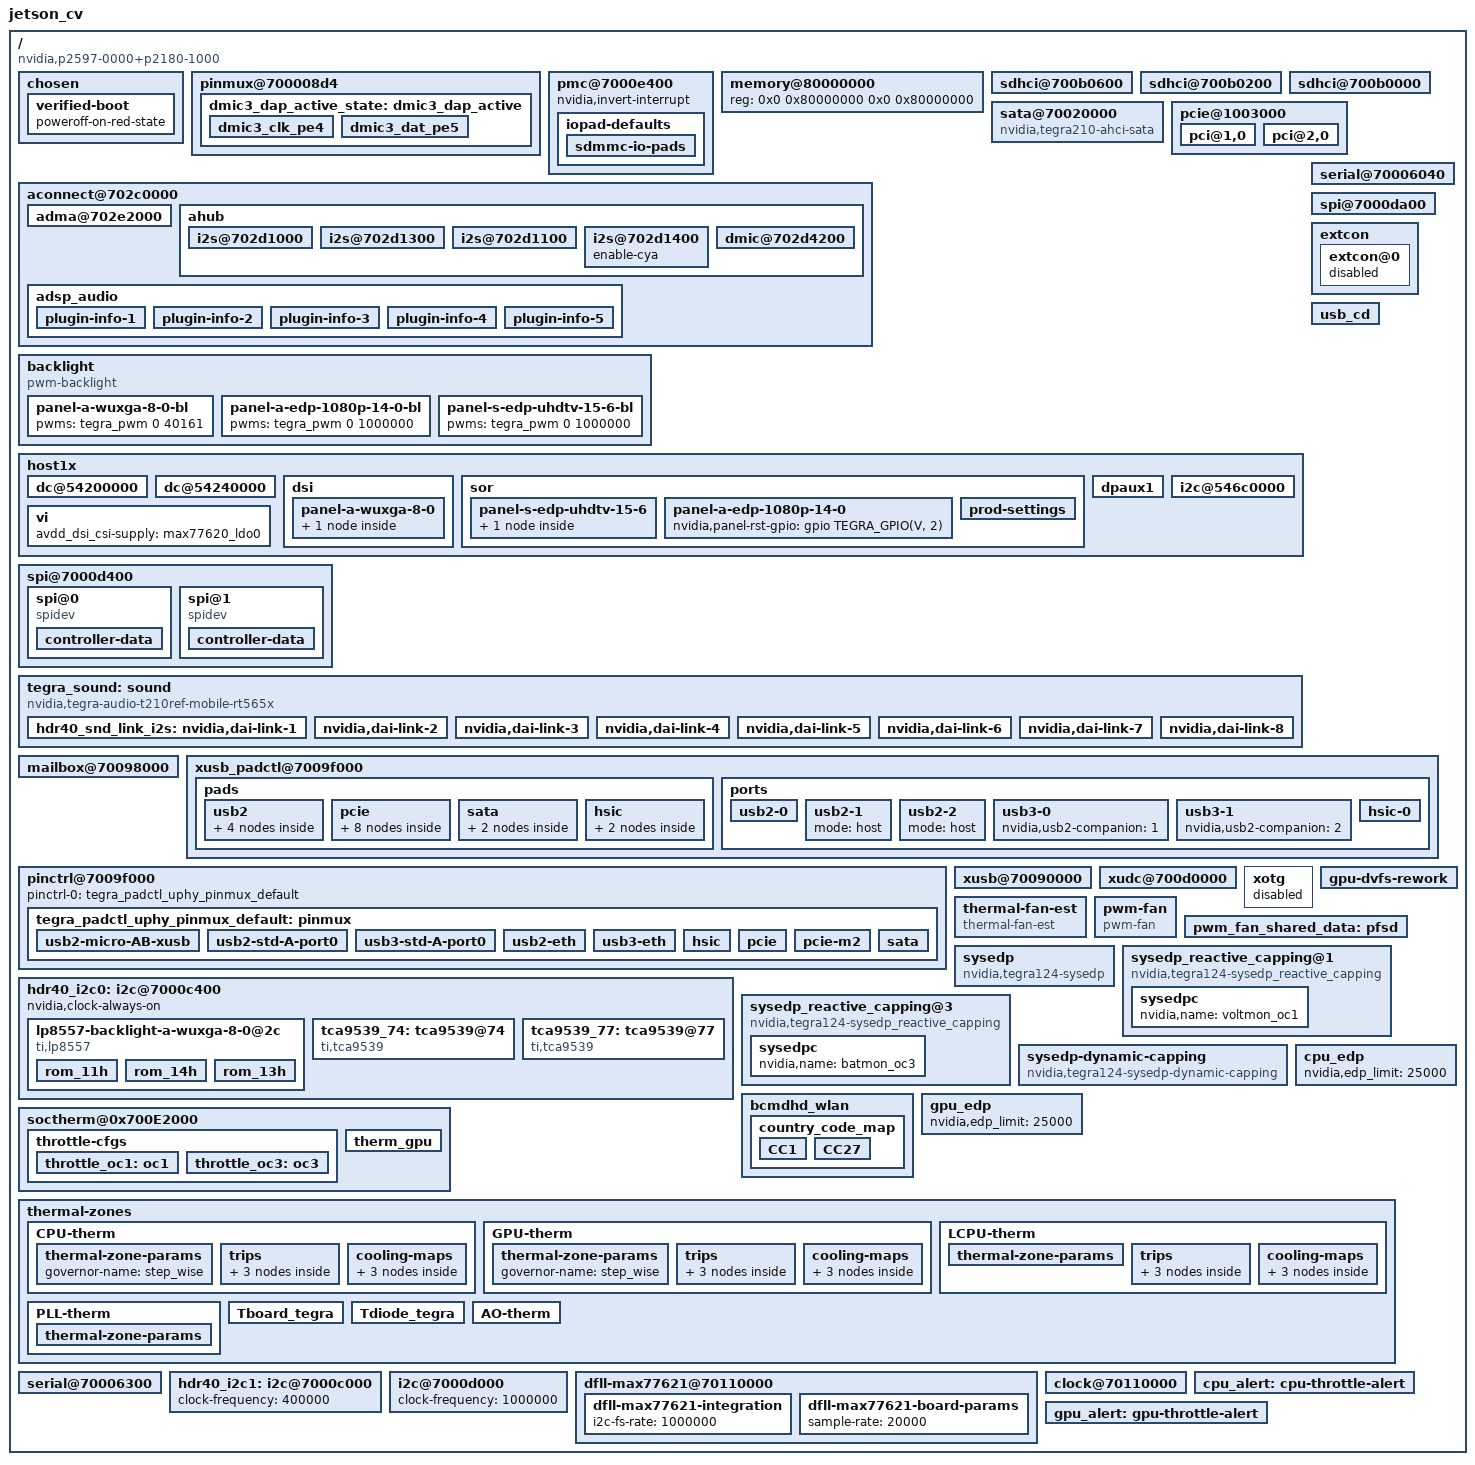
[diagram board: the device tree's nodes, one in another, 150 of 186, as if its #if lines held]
/*
 * arch/arm64/boot/dts/tegra210-jetson-cv-base-p2597-2180-a00.dts
 *
 * Copyright (c) 2015-2020, NVIDIA CORPORATION.  All rights reserved.
 *
 * This program is free software; you can redistribute it and/or modify
 * it under the terms of the GNU General Public License as published by
 * the Free Software Foundation; version 2 of the License.
 *
 * This program is distributed in the hope that it will be useful, but WITHOUT
 * ANY WARRANTY; without even the implied warranty of MERCHANTABILITY or
 * FITNESS FOR A PARTICULAR PURPOSE.  See the GNU General Public License for
 * more details.
 *
 */

/dts-v1/;

/memreserve/ 0x80000000 0x00020000;

#include "tegra210-jetson-common.dtsi"
#include <tegra210-soc/tegra210-audio.dtsi>
#include "jetson-platforms/tegra210-jetson-cv-power-tree-p2597-2180-a00.dtsi"
#include "jetson-platforms/tegra210-jetson-cv-pinmux-p2597-2180-a00.dtsi"
#include "jetson-platforms/tegra210-jetson-cv-gpio-p2597-2180-a00.dtsi"
#include "jetson-platforms/tegra210-jetson-cv-prods.dtsi"
#include "jetson-platforms/tegra210-comms-p2530-0930.dtsi"
#include "jetson-platforms/tegra210-jetson-cv-camera-modules.dtsi"
#include "jetson-platforms/tegra210-pwm-fan-p2530-0930.dtsi"
#include <panels/panel-a-wuxga-8-0.dtsi>
#include <panels/panel-a-edp-1080p-14-0.dtsi>
#include <panels/panel-s-edp-uhdtv-15-6.dtsi>
#include <t210-common-platforms/tegra210-ers-hdmi-e2190-1100-a00.dtsi>
#include <tegra210-soc/tegra210-sdhci.dtsi>
#include "jetson-platforms/tegra210-p2180-common.dtsi"
#include "jetson-platforms/tegra210-thermal-fan-est-p2530-0930.dtsi"
#include "jetson-platforms/tegra210-jetson-cv-keys-p2597-2180-a00.dtsi"
#include <dt-bindings/iio/meter/ina3221x.h>
#include <t210-common-platforms/tegra210-otg-gpio-detection-extcon.dtsi>
#include "jetson-platforms/tegra210-jetson-cv-emc-p2180-1000-a00.dtsi"
#include <tegra210-soc/tegra210-edp.dtsi>
#include <t210-common-platforms/tegra210-sysedp.dtsi>
#include <t210-common-platforms/tegra210-thermal-nct72-p2530.dtsi>
#include <t210-common-platforms/tegra210-thermal-userspace-alert.dtsi>
#include <tegra210-soc/tegra210-thermal-Tboard-Tdiode.dtsi>
#include "jetson-platforms/tegra210-jetson-cv-powermon-p2180-1000-a00.dtsi"
#include "jetson-platforms/tegra210-jetson-cv-powermon-p2597.dtsi"
#include <t210-common-platforms/tegra210-cpufreq.dtsi>
#include "jetson-platforms/tegra210-jetson-cv-super-module-e2614.dtsi"
#include "jetson-plugin-manager/tegra210-jetson-cv-eeprom-manager.dtsi"
#include "jetson-plugin-manager/tegra210-jetson-cv-camera-plugin-manager.dtsi"
#include "jetson-plugin-manager/tegra210-jetson-cv-plugin-manager.dtsi"

/ {
	model = "jetson_cv";
	compatible = "nvidia,p2597-0000+p2180-1000", "nvidia,jetson-cv", "nvidia,tegra210";
	nvidia,dtsfilename = __FILE__;

	#address-cells = <2>;
	#size-cells = <2>;

	chosen {
		board-has-eeprom;
		firmware-blob-partition = "RP4";
		stdout-path = &uarta;
		verified-boot {
			poweroff-on-red-state;
		};
	};

	pinmux@700008d4 {
		/* Dynamic pinmux config for DMIC3 */
		dmic3_dap_active_state: dmic3_dap_active {
			dmic3_clk_pe4 {
				nvidia,pins = "dmic3_clk_pe4";
				nvidia,function = "dmic3";
			};

			dmic3_dat_pe5 {
				nvidia,pins = "dmic3_dat_pe5";
				nvidia,function = "dmic3";
			};
		};
	};

	pmc@7000e400 {
		nvidia,invert-interrupt;

		iopad-defaults {
			sdmmc-io-pads {
				pins = "sdmmc1", "sdmmc3";
				nvidia,enable-voltage-switching;
			};
		};
	};

	memory@80000000 {
		device_type = "memory";
		reg = < 0x0 0x80000000 0x0 0x80000000 >;
	};

	sdhci@700b0600 { /* SDMMC4 for EMMC */
		uhs-mask = <0x0>;
		built-in;
		power-off-rail;
		status = "okay";
		bus-width = <8>;
		non-removable;
	};

	sdhci@700b0200 { /* SDMMC2 for Wifi */
		uhs-mask = <0x8>;
		power-off-rail;
		status = "okay";
	};

	sdhci@700b0000 { /* SDMMC1 for SD card */
		uhs-mask = <0xc>;
		power-off-rail;
		nvidia,update-pinctrl-settings;
		nvidia,sd-device;
		wp-gpios = <&gpio TEGRA_GPIO(Z, 4) 0>;
		status = "okay";
	};

#if TEGRA_AUDIO_BUS_DT_VERSION >= DT_VERSION_2
	aconnect@702c0000 {
#endif
	adma@702e2000  {
		status = "okay";
	};

	ahub {
		i2s@702d1000 {
			pinctrl-names = "dap_active", "dap_inactive";
			pinctrl-0 = <>;
			pinctrl-1 = <>;
			regulator-supplies = "vdd-1v8-audio-hv", "vdd-1v8-audio-hv-bias";
			vdd-1v8-audio-hv-supply = <&max77620_sd3>;
			vdd-1v8-audio-hv-bias-supply = <&max77620_sd3>;
		};

		i2s@702d1300 {
			pinctrl-names = "dap_active", "dap_inactive";
			pinctrl-0 = <>;
			pinctrl-1 = <>;
			regulator-supplies = "vddio-dmic";
			vddio-dmic-supply = <&max77620_sd3>;

			/*
			 * I2S4 on Jetson TX1 uses the I2S4B pads and
			 * to use these pads bit 0 in the I2S_CYA
			 * register must be set.
			 */
			enable-cya;
		};

		i2s@702d1100 {
			pinctrl-names = "dap_active", "dap_inactive";
			pinctrl-0 = <>;
			pinctrl-1 = <>;
			regulator-supplies = "vdd-1v8-spi-hv", "vdd-1v8-spi-hv-bias";
			vdd-1v8-spi-hv-supply = <&max77620_sd3>;
			vdd-1v8-spi-hv-bias-supply = <&max77620_sd3>;
			fsync-width = <0>;
			bclk-ratio = <4>;
		};

		i2s@702d1400 {
			/*
			 * I2S5 on Jetson TX1 uses the I2S5B pads and
			 * to use these pads bit 0 in the I2S_CYA
			 * register must be set.
			 */
			enable-cya;
		};

		dmic@702d4200 {
			pinctrl-names = "dap_active", "dap_inactive";
			pinctrl-0 = <&dmic3_dap_active_state>;
			pinctrl-1 = <>;
		};
	};
#if TEGRA_AUDIO_BUS_DT_VERSION >= DT_VERSION_2
	};
#endif

	sata@70020000 {
		compatible = "nvidia,tegra210-ahci-sata";
		status = "okay";
	};

	backlight {
		compatible = "pwm-backlight";
		status = "okay";
		panel-a-wuxga-8-0-bl {
			status = "okay";
			pwms = <&tegra_pwm 0 40161>;
		};
		panel-a-edp-1080p-14-0-bl {
			pwms = <&tegra_pwm 0 1000000>;
		};
		panel-s-edp-uhdtv-15-6-bl {
			status = "okay";
			pwms = <&tegra_pwm 0 1000000>;
		};
	};

	pcie@1003000 {
		nvidia,wake-gpio = <&gpio TEGRA_GPIO(A, 2) 0>;
		avdd-pll-uerefe-supply = <&max77620_ldo7>;
		hvddio-pex-supply = <&max77620_sd3>;
		dvddio-pex-supply = <&max77620_ldo1>;
		dvdd-pex-pll-supply = <&max77620_ldo1>;
		hvdd-pex-pll-e-supply = <&max77620_sd3>;
		vddio-pex-ctl-supply = <&max77620_sd3>;
		status = "okay";

		pci@1,0 {
#if TEGRA_XUSB_PADCONTROL_VERSION >= DT_VERSION_2
			phys = <&{/xusb_padctl@7009f000/pads/pcie/lanes/pcie-1}>,
				<&{/xusb_padctl@7009f000/pads/pcie/lanes/pcie-2}>,
				<&{/xusb_padctl@7009f000/pads/pcie/lanes/pcie-3}>,
				<&{/xusb_padctl@7009f000/pads/pcie/lanes/pcie-4}>;
			phy-names = "pcie-0", "pcie-1", "pcie-2", "pcie-3";
#endif
			nvidia,num-lanes = <4>;
			status = "okay";
		};

		pci@2,0 {
#if TEGRA_XUSB_PADCONTROL_VERSION >= DT_VERSION_2
			phys = <&{/xusb_padctl@7009f000/pads/pcie/lanes/pcie-0}>;
			phy-names = "pcie-0";
#endif
			nvidia,num-lanes = <1>;
			status = "okay";
		};
	};

	host1x {
		assigned-clocks = <&tegra_car TEGRA210_CLK_EXTERN3>,
						<&tegra_car TEGRA210_CLK_CILE>,
						<&tegra_car TEGRA210_CLK_CILCD>,
						<&tegra_car TEGRA210_CLK_CILAB>,
						<&tegra_car TEGRA210_CLK_VI_I2C>,
						<&tegra_car TEGRA210_CLK_CLK_OUT_3_MUX>,
						<&tegra_car TEGRA210_CLK_VI>,
						<&tegra_car TEGRA210_CLK_ISP>,
						<&tegra_car TEGRA210_CLK_ISPB>;
		assigned-clock-parents = <&tegra_car TEGRA210_CLK_PLL_P>,
						<&tegra_car TEGRA210_CLK_PLL_P>,
						<&tegra_car TEGRA210_CLK_PLL_P>,
						<&tegra_car TEGRA210_CLK_PLL_P>,
						<&tegra_car TEGRA210_CLK_PLL_P>,
						<&tegra_car TEGRA210_CLK_EXTERN3>,
						<&tegra_car TEGRA210_CLK_PLL_C>,
						<&tegra_car TEGRA210_CLK_PLL_C>,
						<&tegra_car TEGRA210_CLK_ISP>;
		assigned-clock-rates = <24000000>,
						<102000000>,
						<102000000>,
						<102000000>,
						<102000000>,
						<24000000>,
						<408000000>,
						<408000000>,
						<0>;

		/* tegradc.0 */
		dc@54200000 {
			status = "okay";
			nvidia,dc-flags = <TEGRA_DC_FLAG_ENABLED>;
			nvidia,emc-clk-rate = <300000000>;
			nvidia,fb-bpp = <32>; /* bits per pixel */
			nvidia,fb-flags = <TEGRA_FB_FLIP_ON_PROBE>;
			nvidia,dc-or-node = "/host1x/dsi";
			nvidia,dc-connector = <&dsi>;
			win-mask = <0x7>; /* Assign only wins A/B/C */
		};

		/* tegradc.1 */
		dc@54240000 {
			status = "okay";
			nvidia,dc-flags = <TEGRA_DC_FLAG_ENABLED>;
			nvidia,emc-clk-rate = <300000000>;
			nvidia,cmu-enable = <1>;
			nvidia,fb-bpp = <32>; /* bits per pixel */
			nvidia,fb-flags = <TEGRA_FB_FLIP_ON_PROBE>;
			nvidia,dc-or-node = "/host1x/sor1";
			nvidia,dc-connector = <&sor1>;
			win-mask = <0x7>; /* Assign only wins A/B/C */
		};

		dsi {
			nvidia,dsi-controller-vs = <DSI_VS_1>;
			status = "okay";
			nvidia,active-panel = <&panel_a_wuxga_8_0>;
			panel-a-wuxga-8-0 {
				status = "okay";
				nvidia,dsi-dpd-pads = <DSIC_DPD_EN DSID_DPD_EN>;
				nvidia,panel-rst-gpio = <&gpio TEGRA_GPIO(V, 2) 0>; /* PV2 */
				nvidia,panel-bl-pwm-gpio = <&gpio TEGRA_GPIO(V, 0) 0>; /* PV0 */
				disp-default-out {
					nvidia,out-flags = <TEGRA_DC_OUT_CONTINUOUS_MODE>;
				};
			};
		};

		sor {
			status = "okay";
			nvidia,hpd-gpio = <&gpio TEGRA_GPIO(CC, 6) 0>; /* PCC6 */
			nvidia,active-panel = <&panel_s_edp_uhdtv_15_6>;
			panel-s-edp-uhdtv-15-6 {
				status = "okay";
				nvidia,panel-bl-pwm-gpio = <&gpio TEGRA_GPIO(V, 0) 0>; /* PV0 */
				nvidia,panel-rst-gpio = <&gpio TEGRA_GPIO(V, 2) 0>; /* PV2 */
				smartdimmer {
					status = "okay";
				};
			};
			panel-a-edp-1080p-14-0 {
				nvidia,panel-rst-gpio = <&gpio TEGRA_GPIO(V, 2) 0>; /* PV2 */
			};
			prod-settings {
				status = "okay";
			};
		};

		dpaux1 {
			status = "okay";
		};

		i2c@546c0000 {
			status = "okay";
			bus-pullup-supply = <&max77620_sd3>;
			avdd_dsi_csi-supply = <&max77620_ldo0>;
		};

		vi {
			status = "okay";
			avdd_dsi_csi-supply = <&max77620_ldo0>;
		};
	};

	serial@70006040 {
		status = "okay";
	};

	spi@7000da00 {
		status = "ok";
	};

	spi@7000d400 {
		status = "okay";
		spi@0 {
			compatible = "spidev";
			reg = <0x0>;
			spi-max-frequency = <33000000>;
			controller-data {
				nvidia,enable-hw-based-cs;
				nvidia,rx-clk-tap-delay = <7>;
			};
		};
		spi@1 {
			compatible = "spidev";
			reg = <0x1>;
			spi-max-frequency = <33000000>;
			controller-data {
				nvidia,enable-hw-based-cs;
				nvidia,rx-clk-tap-delay = <7>;
			};
		};
	};

	tegra_sound: sound {
		compatible = "nvidia,tegra-audio-t210ref-mobile-rt565x";
		nvidia,model = "tegra-snd-t210ref-mobile-rt565x";

		clocks = <&tegra_car TEGRA210_CLK_PLL_A>,
			 <&tegra_car TEGRA210_CLK_PLL_A_OUT0>,
			 <&tegra_car TEGRA210_CLK_EXTERN1>;
		clock-names = "pll_a", "pll_a_out0", "extern1";
		assigned-clocks = <&tegra_car TEGRA210_CLK_EXTERN1>,
				  <&tegra_car TEGRA210_CLK_PLL_A_OUT0>,
				  <&tegra_car TEGRA210_CLK_PLL_A>;
		assigned-clock-parents = <&tegra_car TEGRA210_CLK_PLL_A_OUT0>;
		assigned-clock-rates = <12288000>, <49152000>, <368640000>;

		nvidia,num-codec-link = <8>;

		nvidia,audio-routing =
			"x Headphone",		"x OUT",
			"x IN",			"x Mic",
			"y Headphone",		"y OUT",
			"y IN",			"y Mic",
			"l Headphone",		"l OUT",
			"l IN",			"l Mic",
			"s Headphone",		"s OUT",
			"s IN",			"s Mic",
			"w Headphone",		"w OUT",
			"w IN",			"w Mic",
			"z IN",			"z Mic",
			"m IN",			"m Mic",
			"n IN",			"n Mic";

		nvidia,xbar = <&tegra_axbar>;
		mclk-fs = <256>;

		hdr40_snd_link_i2s: nvidia,dai-link-1 {
			link-name = "spdif-dit-0";
			cpu-dai = <&tegra_i2s1>;
			codec-dai = <&spdif_dit4>;
			cpu-dai-name = "I2S1";
			codec-dai-name = "dit-hifi";
			format = "i2s";
			bit-format = "s16_le";
			srate = <48000>;
			num-channel = <2>;
			name-prefix = "x";
		};

		nvidia,dai-link-2 {
			link-name = "spdif-dit-1";
			cpu-dai = <&tegra_i2s2>;
			codec-dai = <&spdif_dit1>;
			cpu-dai-name = "I2S2";
			codec-dai-name = "dit-hifi";
			format = "dsp_a";
			bitclock-inversion;
			bit-format = "s16_le";
			srate = <8000>;
			num-channel = <1>;
			name-prefix = "y";
		};

		nvidia,dai-link-3 {
			link-name = "spdif-dit-2";
			cpu-dai = <&tegra_dmic3>;
			codec-dai = <&spdif_dit2>;
			cpu-dai-name = "DMIC3";
			codec-dai-name = "dit-hifi";
			format = "i2s";
			bit-format = "s16_le";
			srate = <48000>;
			num-channel = <2>;
			name-prefix = "z";
		};

		nvidia,dai-link-4 {
			link-name = "spdif-dit-3";
			cpu-dai = <&tegra_i2s3>;
			codec-dai = <&spdif_dit3>;
			cpu-dai-name = "I2S3";
			codec-dai-name = "dit-hifi";
			format = "i2s";
			bit-format = "s16_le";
			srate = <48000>;
			num-channel = <2>;
			name-prefix = "l";
		};

		nvidia,dai-link-5 {
			link-name = "spdif-dit-4";
			cpu-dai = <&tegra_i2s4>;
			codec-dai = <&spdif_dit0>;
			cpu-dai-name = "I2S4";
			codec-dai-name = "dit-hifi";
			format = "i2s";
			bit-format = "s16_le";
			srate = <48000>;
			num-channel = <2>;
			name-prefix = "s";
		};

		nvidia,dai-link-6 {
			link-name = "spdif-dit-5";
			cpu-dai = <&tegra_i2s5>;
			codec-dai = <&spdif_dit5>;
			cpu-dai-name = "I2S5";
			codec-dai-name = "dit-hifi";
			format = "i2s";
			bit-format = "s16_le";
			srate = <48000>;
			num-channel = <2>;
			name-prefix = "w";
		};
		nvidia,dai-link-7 {
			link-name = "spdif-dit-6";
			cpu-dai = <&tegra_dmic1>;
			codec-dai = <&spdif_dit6>;
			cpu-dai-name = "DMIC1";
			codec-dai-name = "dit-hifi";
			format = "i2s";
			bit-format = "s16_le";
			srate = <48000>;
			num-channel = <2>;
			name-prefix = "m";
		};
		nvidia,dai-link-8 {
			link-name = "spdif-dit-7";
			cpu-dai = <&tegra_dmic2>;
			codec-dai = <&spdif_dit7>;
			cpu-dai-name = "DMIC2";
			codec-dai-name = "dit-hifi";
			format = "i2s";
			bit-format = "s16_le";
			srate = <48000>;
			num-channel = <2>;
			name-prefix = "n";
		};
	};

#if TEGRA_AUDIO_BUS_DT_VERSION >= DT_VERSION_2
	aconnect@702c0000 {
#endif
	adsp_audio {
		compr-ops = <1>;
		num-plugin = <5>;
		plugin-info-1 {
			plugin-name = "mp3-dec1";
			firmware-name = "nvmp3dec.elf";
			widget-name = "MP3-DEC1";
		};
		plugin-info-2 {
			plugin-name = "spkprot";
			firmware-name = "nvspkprot.elf";
			widget-name = "SPKPROT-SW";
		};
		plugin-info-3 {
			plugin-name = "src";
			firmware-name = "nvsrc.elf";
			widget-name = "SRC";
		};
		plugin-info-4 {
			plugin-name = "aac-dec1";
			firmware-name = "nvaacdec.elf";
			widget-name = "AAC-DEC1";
		};
		plugin-info-5 {
			plugin-name = "aec";
			firmware-name = "nvoice.elf";
			widget-name = "AEC";
		};
	};
#if TEGRA_AUDIO_BUS_DT_VERSION >= DT_VERSION_2
	};
#endif

	extcon {
		extcon@0 {
			status = "disabled";
		};
	};

	mailbox@70098000 {
		status = "okay";
	};

	usb_cd {
		status = "okay";
#if TEGRA_XUSB_PADCONTROL_VERSION >= DT_VERSION_2
		phys = <&{/xusb_padctl@7009f000/pads/usb2/lanes/usb2-0}>;
#else
		phys = <&tegra_padctl_uphy TEGRA_PADCTL_UPHY_UTMI_P(0)>;
#endif
		phy-names = "otg-phy";
	};

#if TEGRA_XUSB_PADCONTROL_VERSION >= DT_VERSION_2
	xusb_padctl@7009f000 {
		status = "okay";

		pads {
			usb2 {
				status = "okay";

				lanes {
					usb2-0 {
						status = "okay";
						nvidia,function = "xusb";
					};
					usb2-1 {
						status = "okay";
						nvidia,function = "xusb";
					};
					usb2-2 {
						status = "okay";
						nvidia,function = "xusb";
					};
				};
			};

			pcie {
				status = "okay";

				lanes {
					pcie-0 {
						status = "okay";
						nvidia,function = "pcie-x1";
					};
					pcie-1 {
						status = "okay";
						nvidia,function = "pcie-x4";
					};
					pcie-2 {
						status = "okay";
						nvidia,function = "pcie-x4";
					};
					pcie-3 {
						status = "okay";
						nvidia,function = "pcie-x4";
					};
					pcie-4 {
						status = "okay";
						nvidia,function = "pcie-x4";
					};
					pcie-5 {
						status = "okay";
						nvidia,function = "xusb";
					};
					pcie-6 {
						status = "okay";
						nvidia,function = "xusb";
					};
				};
			};

			sata {
				status = "okay";

				lanes {
					sata-0 {
						status = "okay";
						nvidia,function = "sata";
					};
				};
			};

			hsic {
				status = "okay";

				lanes {
					hsic-0 {
						status = "okay";
						nvidia,function = "xusb";
					};
				};
			};
		};

		ports {
			usb2-0 {
				status = "okay";
				mode = "otg";
				nvidia,usb3-port-fake = <3>;
			};
			usb2-1 {
				status = "okay";
				mode = "host";
			};
			usb2-2 {
				status = "okay";
				mode = "host";
			};
			usb3-0 {
				status = "okay";
				nvidia,usb2-companion = <1>;
			};
			usb3-1 {
				status = "okay";
				nvidia,usb2-companion = <2>;
			};
			hsic-0 {
				status = "okay";
			};
		};
	};
#endif

	pinctrl@7009f000 {
		status = "okay";
		pinctrl-0 = <&tegra_padctl_uphy_pinmux_default>;
		pinctrl-names = "default";
		tegra_padctl_uphy_pinmux_default: pinmux {
			usb2-micro-AB-xusb {
				nvidia,lanes = "otg-0";
				nvidia,function = "xusb";
				nvidia,port-cap =
					<TEGRA_PADCTL_PORT_OTG_CAP>;
				nvidia,usb3-port-fake = <3>;
			};
			usb2-std-A-port0 {
				 nvidia,lanes = "otg-2";
				 nvidia,function = "xusb";
				 nvidia,port-cap =
					<TEGRA_PADCTL_PORT_HOST_ONLY>;
			};
			usb3-std-A-port0 {
				 nvidia,lanes = "uphy-lane-5";
				 nvidia,function = "usb3";
				 nvidia,usb3-port = <1>;
				 nvidia,usb2-map = <2>;
				 nvidia,port-cap =
					<TEGRA_PADCTL_PORT_HOST_ONLY>;
			};
			usb2-eth {
				 nvidia,lanes = "otg-1";
				 nvidia,function = "xusb";
				 nvidia,port-cap =
					<TEGRA_PADCTL_PORT_HOST_ONLY>;
			};
			usb3-eth {
				 nvidia,lanes = "uphy-lane-6";
				 nvidia,function = "usb3";
				 nvidia,usb3-port = <0>;
				 nvidia,usb2-map = <1>;
				 nvidia,port-cap =
					<TEGRA_PADCTL_PORT_HOST_ONLY>;
			};
			hsic {
				 nvidia,lanes = "hsic-0";
				 nvidia,function = "hsic";
			};
			pcie {
				 nvidia,lanes =	"uphy-lane-1", "uphy-lane-2",
						"uphy-lane-3", "uphy-lane-4";
				 nvidia,function = "pcie";
				 nvidia,pcie-controller = <0>;
				 nvidia,pcie-lane-select =
					<TEGRA_PADCTL_PCIE_LANE_X4>;
			};
			pcie-m2 {
				nvidia,lanes = "uphy-lane-0";
				nvidia,function = "pcie";
				nvidia,pcie-controller = <1>;
				nvidia,pcie-lane-select =
					<TEGRA_PADCTL_PCIE_LANE_X1>;
			};
			sata {
				 nvidia,lanes = "uphy-lane-7";
				 nvidia,function = "sata";
			};
		};
	};

	xusb@70090000 {
		status = "okay";
		extcon-cables = <&vbus_gpio_extcon 1>;
		extcon-cable-names = "id";
		#extcon-cells = <1>;
#if TEGRA_XUSB_PADCONTROL_VERSION >= DT_VERSION_2
		phys = <&{/xusb_padctl@7009f000/pads/usb2/lanes/usb2-0}>,
		       <&{/xusb_padctl@7009f000/pads/usb2/lanes/usb2-1}>,
		       <&{/xusb_padctl@7009f000/pads/usb2/lanes/usb2-2}>,
		       <&{/xusb_padctl@7009f000/pads/pcie/lanes/pcie-6}>,
		       <&{/xusb_padctl@7009f000/pads/pcie/lanes/pcie-5}>;
		phy-names = "usb2-0", "usb2-1", "usb2-2", "usb3-0", "usb3-1";
#else
		phys =	<&tegra_padctl_uphy TEGRA_PADCTL_UPHY_UTMI_P(2)>,
			<&tegra_padctl_uphy TEGRA_PADCTL_UPHY_USB3_P(1)>,
			<&tegra_padctl_uphy TEGRA_PADCTL_UPHY_UTMI_P(1)>,
			<&tegra_padctl_uphy TEGRA_PADCTL_UPHY_USB3_P(0)>,
			<&tegra_padctl_uphy TEGRA_PADCTL_UPHY_UTMI_P(0)>;
		phy-names = "utmi-2", "usb3-1", "utmi-1", "usb3-0", "utmi-0";
#endif
		nvidia,pmc-wakeup =
			<&tegra_pmc
				PMC_WAKE_TYPE_EVENT 39 PMC_TRIGGER_TYPE_HIGH>,
			<&tegra_pmc
				PMC_WAKE_TYPE_EVENT 41 PMC_TRIGGER_TYPE_HIGH>,
			<&tegra_pmc
				PMC_WAKE_TYPE_EVENT 44 PMC_TRIGGER_TYPE_HIGH>;
		nvidia,boost_cpu_freq = <1200>;
	};

	xudc@700d0000 {
		#extcon-cells = <1>;
		status = "okay";
#if TEGRA_XUSB_PADCONTROL_VERSION >= DT_VERSION_2
		phys = <&{/xusb_padctl@7009f000/pads/usb2/lanes/usb2-0}>;
#else
		phys =  <&tegra_padctl_uphy TEGRA_PADCTL_UPHY_UTMI_P(0)>;
#endif
		phy-names = "usb2";
	};

	xotg {
		#extcon-cells = <1>;
		status = "disabled";
	};

	gpu-dvfs-rework {
		status = "ok";
	};

	thermal-fan-est {
		compatible = "thermal-fan-est";
		active_trip_temps = <0 51000 61000 71000 82000
				140000 150000 160000 170000 180000>;
		active_hysteresis = <0 15000 9000 9000 10000
				0 0 0 0 0>;
	};

	pwm-fan {
		compatible = "pwm-fan";
		pwms = <&tegra_pwm 3 45334>;
		shared_data = <&pwm_fan_shared_data>;
		active_pwm = <0 80 120 160 255 255 255 255 255 255>;
	};

	pwm_fan_shared_data: pfsd {
		tach_gpio =  <&gpio TEGRA_GPIO(K, 7) GPIO_ACTIVE_LOW>; /* TEGRA_GPIO_PK7 */
	};

	hdr40_i2c0: i2c@7000c400 {
		nvidia,clock-always-on;

		lp8557-backlight-a-wuxga-8-0@2c {
			status = "okay";
			disable-on-kernel-charging;
			compatible = "ti,lp8557";
			reg = <0x2c>;
			power-supply = <&battery_reg>;

			bl-name = "pwm-backlight"; /* Match liblights naming expectations */
			init-brt = /bits/ 8 <0xFF>; /* Max brightness */
			dev-ctrl = /bits/ 8 <0x80>; /* PWM, enable standby mode */
			pwm-period = <29334>;

			pwm-names = "lp8557";
			pwms = <&tegra_pwm 0 29334>;

			bl-measured = < 0 1 2 3 4 5 6 7
					8 9 10 11 12 13 14 15
					16 17 18 19 20 21 22 23
					24 25 26 27 28 29 30 31
					32 33 34 35 36 37 38 39
					40 41 42 43 44 45 46 47
					48 49 50 51 52 53 54 55
					56 57 58 59 60 61 62 63
					64 65 66 67 68 69 70 71
					72 73 74 75 76 77 78 79
					80 81 82 83 84 85 86 87
					88 89 90 91 92 93 94 95
					96 97 98 99 100 101 102 103
					104 105 106 107 108 109 110 111
					112 113 114 115 116 117 118 119
					120 121 122 123 124 125 126 127
					128 129 130 131 132 133 134 135
					136 137 138 139 140 141 142 143
					144 145 146 147 148 149 150 151
					152 153 154 155 156 157 158 159
					160 161 162 163 164 165 166 167
					168 169 170 171 172 173 174 175
					176 177 178 179 180 181 182 183
					184 185 186 187 188 189 190 191
					192 193 194 195 196 197 198 199
					200 201 202 203 204 205 206 207
					208 209 210 211 212 213 214 215
					216 217 218 219 220 221 222 223
					224 225 226 227 228 229 230 231
					232 233 234 235 236 237 238 239
					240 241 242 243 244 245 246 247
					248 249 250 251 252 253 254 255 >;

			/* 20 mA max current */
			rom_11h {
				rom-addr = /bits/ 8 <0x11>;
				rom-val = /bits/ 8 <0x05>;
			};

			/* 3 LED string */
			rom_14h {
				rom-addr = /bits/ 8 <0x14>;
				rom-val = /bits/ 8 <0x87>;
			};

			/*Boost freq 1MHZ*/
			rom_13h {
				rom-addr = /bits/ 8 <0x13>;
				rom-val = /bits/ 8 <0x01>;
			};
		};

		tca9539_74: tca9539@74 {
			compatible = "ti,tca9539";
			gpio-controller;
			#gpio-cells = <2>;
			reg = <0x74>;
			interrupt-parent = <&gpio>;
			interrupts = <TEGRA_GPIO(L, 1) 0x0>;
			#interrupt-cells = <2>;
			interrupt-controller;
			vcc-supply = <&battery_reg>;
		};

		tca9539_77: tca9539@77 {
			compatible = "ti,tca9539";
			gpio-controller;
			#gpio-cells = <2>;
			reg = <0x77>;
			interrupt-parent = <&gpio>;
			interrupts = <TEGRA_GPIO(Z, 2) 0x0>;
			#interrupt-cells = <2>;
			interrupt-controller;
			vcc-supply = <&battery_reg>;
		};
	};

	sysedp {
		compatible = "nvidia,tegra124-sysedp";
		nvidia,margin = <0>;
		nvidia,min_budget = <0>;
		nvidia,initial_budget = <40000>;
	};

	sysedp_reactive_capping@1 {
		compatible = "nvidia,tegra124-sysedp_reactive_capping";
		nvidia,max_capping_mw = <15000>;
		nvidia,step_alarm_mw = <1000>;
		nvidia,step_relax_mw = <500>;
		nvidia,relax_ms = <250>;
		nvidia,threshold_warning = "WARNING - SYSTEM Voltage Droop detected, please refer to the Jetson Power management application note";
		interrupt-parent = <&soctherm>;
		interrupts = <1 0x2002>;
		sysedpc {
			nvidia,name = "voltmon_oc1";
		};
	};

	sysedp_reactive_capping@3 {
		compatible = "nvidia,tegra124-sysedp_reactive_capping";
		nvidia,max_capping_mw = <15000>;
		nvidia,step_alarm_mw = <1000>;
		nvidia,step_relax_mw = <500>;
		nvidia,relax_ms = <250>;
		nvidia,threshold_warning = "WARNING - Battery Over Current Limit hit, please refer to the Jetson Power management application note";
		interrupt-parent = <&soctherm>;
		interrupts = <3 0x2002>;
		sysedpc {
			nvidia,name = "batmon_oc3";
		};
	};

	sysedp-dynamic-capping {
		compatible = "nvidia,tegra124-sysedp-dynamic-capping";
		nvidia,throttle_depth = <75>;
		nvidia,cap_method = <1>;
	};

	bcmdhd_wlan {
		edp-consumer-name = "primary-wifi";
	};

	cpu_edp {
		status = "okay";
		nvidia,edp_limit = <25000>;
	};

	gpu_edp {
		status = "okay";
		nvidia,edp_limit = <25000>;
	};

	soctherm@0x700E2000 {
		throttle-cfgs {
			throttle_oc1: oc1 {
				nvidia,priority = <50>;
				nvidia,polarity-active-low = <1>;
				nvidia,count-threshold = <100>;
				nvidia,alarm-filter = <5100000>;
				nvidia,alarm-period = <0>;
				nvidia,cpu-throt-percent = <75>;
				nvidia,gpu-throt-level =
					<TEGRA_SOCTHERM_THROT_LEVEL_MED>;
			};
			throttle_oc3: oc3 {
				nvidia,priority = <40>;
				nvidia,polarity-active-low = <1>;
				nvidia,count-threshold = <15>;
				nvidia,alarm-filter = <5100000>;
				nvidia,alarm-period = <0>;
				nvidia,cpu-throt-percent = <0>;
				nvidia,gpu-throt-level =
					<TEGRA_SOCTHERM_THROT_LEVEL_NONE>;
			};
		};
	};

	thermal-zones {
		CPU-therm {
			thermal-zone-params {
				governor-name = "step_wise";
			};
			trips {
				cpu_critical {
					temperature = <102000>;
					hysteresis = <0>;
					type = "critical";
					writable;
				};
				cpu_heavy {
					temperature = <100500>;
					hysteresis = <0>;
					type = "hot";
					writable;
				};
				cpu_throttle {
					temperature = <97000>;
					hysteresis = <0>;
					type = "passive";
					writable;
				};
			};
			cooling-maps {
				map0 {
					trip = <&{/thermal-zones/CPU-therm/trips/cpu_critical}>;
					cdev-type = "tegra-shutdown";
					cooling-device = <&{/soctherm@0x700E2000/throttle@critical}
						THERMAL_NO_LIMIT THERMAL_NO_LIMIT>;
				};
				map1 {
					trip = <&{/thermal-zones/CPU-therm/trips/cpu_heavy}>;
					cdev-type = "tegra-heavy";
					cooling-device = <&throttle_heavy 1 1>;
				};
				map2 {
					trip = <&{/thermal-zones/CPU-therm/trips/cpu_throttle}>;
					cdev-type = "cpu-balanced";
					cooling-device = <&{/bthrot_cdev/cpu_balanced}
						THERMAL_NO_LIMIT THERMAL_NO_LIMIT>;
				};
			};
		};
		GPU-therm {
			thermal-zone-params {
				governor-name = "step_wise";
			};
			trips {
				gpu_critical {
					temperature = <102500>;
					hysteresis = <0>;
					type = "critical";
					writable;
				};
				gpu_heavy {
					temperature = <101000>;
					hysteresis = <0>;
					type = "hot";
					writable;
				};
				gpu_throttle {
					temperature = <97500>;
					hysteresis = <0>;
					type = "passive";
					writable;
				};
			};
			cooling-maps {
				map0 {
					trip = <&{/thermal-zones/GPU-therm/trips/gpu_critical}>;
					cdev-type = "tegra-shutdown";
					cooling-device = <&{/soctherm@0x700E2000/throttle@critical}
						THERMAL_NO_LIMIT THERMAL_NO_LIMIT>;
				};
				map1 {
					trip = <&{/thermal-zones/GPU-therm/trips/gpu_heavy}>;
					cdev-type = "tegra-heavy";
					cooling-device = <&throttle_heavy 1 1>;
				};
				map2 {
					trip = <&{/thermal-zones/GPU-therm/trips/gpu_throttle}>;
					cdev-type = "gpu-balanced";
					cooling-device = <&{/bthrot_cdev/gpu_balanced}
						THERMAL_NO_LIMIT THERMAL_NO_LIMIT>;
				};
			};
		};
		LCPU-therm {
			thermal-zone-params {
				governor-name = "pid_thermal_gov";
				max_err_temp = <9000>;
				max_err_gain = <1000>;
				gain_p = <1000>;
				gain_d = <0>;
				up_compensation = <20>;
				down_compensation = <20>;
			};
			trips {
				lcpu_critical {
					temperature = <103000>; /* must be same as GPU's critical temp */
					hysteresis = <0>;
					type = "critical";
					writable;
				};
				lcpu_heavy {
					temperature = <101500>;
					hysteresis = <0>;
					type = "hot";
					writable;
				};
				lcpu_throttle {
					temperature = <92000>;
					hysteresis = <0>;
					type = "passive";
					writable;
				};
			};
			cooling-maps {
				map0 {
					trip = <&{/thermal-zones/LCPU-therm/trips/lcpu_critical}>;
					cdev-type = "tegra-shutdown";
					cooling-device = <&{/soctherm@0x700E2000/throttle@critical}
						THERMAL_NO_LIMIT THERMAL_NO_LIMIT>;
				};
				map1 {
					trip = <&{/thermal-zones/LCPU-therm/trips/lcpu_heavy}>;
					cdev-type = "tegra-heavy";
					cooling-device = <&throttle_heavy 1 1>;
				};
				map2 {
					trip = <&{/thermal-zones/LCPU-therm/trips/lcpu_throttle}>;
					cdev-type = "cpu-balanced";
					cooling-device = <&{/bthrot_cdev/cpu_balanced}
						THERMAL_NO_LIMIT THERMAL_NO_LIMIT>;
				};
			};
		};
		PLL-therm {
			thermal-zone-params {
				governor-name = "pid_thermal_gov";
				max_err_temp = <9000>;
				max_err_gain = <1000>;
				gain_p = <1000>;
				gain_d = <0>;
				up_compensation = <20>;
				down_compensation = <20>;
			};
		};

		Tboard_tegra {
			status = "okay";
		};
		Tdiode_tegra {
			status = "okay";
		};
		AO-therm {
			status = "okay";
		};
	};

	bcmdhd_wlan {
		fw_path = "/vendor/firmware/fw_bcmdhd.bin";
		nv_path = "/vendor/firmware/nvram_jetsonE_cv_4354.txt";
		country_code_map {
			CC1 {
				iso_abbrev = "XR";
				custom_locale = "XR";
				custom_locale_rev = <122>;
			};
			CC27 {
				iso_abbrev = "IN";
				custom_locale = "Q2";
				custom_locale_rev = <998>;
			};
		};
	};

	serial@70006300 {
		dma-names = "tx";
	};

	hdr40_i2c1: i2c@7000c000 {
		clock-frequency = <400000>;
	};

	i2c@7000d000 {
		clock-frequency = <1000000>;
	};

	dfll-max77621@70110000 {
		dfll-max77621-integration {
			i2c-fs-rate = <1000000>;
		};

		dfll-max77621-board-params {
			sample-rate = <20000>;
		};
	};

	soctherm@0x700E2000 {
		therm_gpu {
			enable-hw-pllx-offsetting;
			pllx-offset-max = <4000>;
			pllx-offset-min = <2000>;
		};
	};

	clock@70110000 {
		status = "okay";
		vdd-cpu-supply = <&cpu_ovr_reg>;
		nvidia,pwm-to-pmic;
		nvidia,init-uv = <1000000>;
		nvidia,align-step-uv = <19200>; /* 19.2mv */
		nvidia,align-offset-uv = <708000>; /* 708mv */
		nvidia,sample-rate = <25000>;
		nvidia,droop-ctrl = <0x00000f00>;
		nvidia,force-mode = <1>;
		nvidia,cf = <6>;
		nvidia,ci = <0>;
		nvidia,cg = <2>;
		nvidia,idle-override;
		nvidia,one-shot-calibrate;
		nvidia,pwm-period = <2500>; /* 2.5us */
		pinctrl-names = "dvfs_pwm_enable", "dvfs_pwm_disable";
		pinctrl-0 = <&dvfs_pwm_active_state>;
		pinctrl-1 = <&dvfs_pwm_inactive_state>;
	};

	cpu_alert: cpu-throttle-alert {
		status = "okay";
	};

	gpu_alert: gpu-throttle-alert {
		status = "okay";
	};
};
